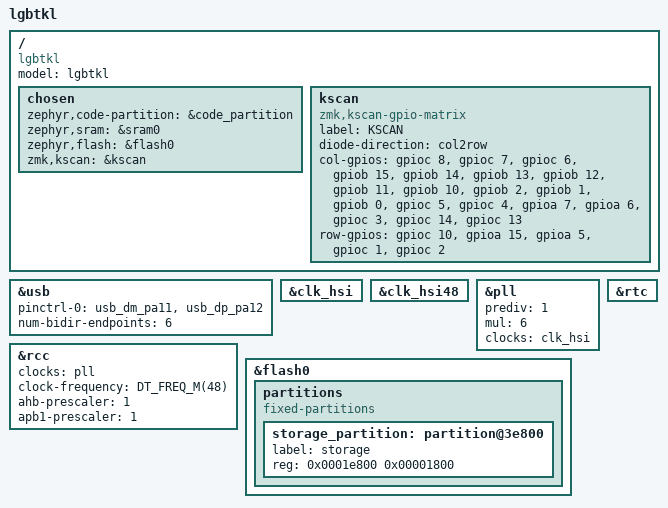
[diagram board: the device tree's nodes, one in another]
/*
 * Copyright (c) 2020 The ZMK Contributors
 *
 * SPDX-License-Identifier: MIT
 */

/dts-v1/;
#include <st/f0/stm32f072Xb.dtsi>
#include <st/f0/stm32f072v(8-b)tx-pinctrl.dtsi>

#include "lgbtkl-transforms.dtsi"
#include "lgbtkl-layouts.dtsi"

/ {
    model = "lgbtkl";
    compatible = "lgbtkl", "st,stm32f072";

    chosen {
        zephyr,code-partition = &code_partition;
        zephyr,sram = &sram0;
        zephyr,flash = &flash0;
        zmk,kscan = &kscan;
    };

    kscan: kscan {
        compatible = "zmk,kscan-gpio-matrix";
        label = "KSCAN";

        diode-direction = "col2row";

        col-gpios
        = <&gpioc 8 (GPIO_ACTIVE_HIGH | GPIO_PULL_DOWN)>
        , <&gpioc 7 (GPIO_ACTIVE_HIGH | GPIO_PULL_DOWN)>
        , <&gpioc 6 (GPIO_ACTIVE_HIGH | GPIO_PULL_DOWN)>
        , <&gpiob 15 (GPIO_ACTIVE_HIGH | GPIO_PULL_DOWN)>
        , <&gpiob 14 (GPIO_ACTIVE_HIGH | GPIO_PULL_DOWN)>
        , <&gpiob 13 (GPIO_ACTIVE_HIGH | GPIO_PULL_DOWN)>
        , <&gpiob 12 (GPIO_ACTIVE_HIGH | GPIO_PULL_DOWN)>
        , <&gpiob 11 (GPIO_ACTIVE_HIGH | GPIO_PULL_DOWN)>
        , <&gpiob 10 (GPIO_ACTIVE_HIGH | GPIO_PULL_DOWN)>
        , <&gpiob 2  (GPIO_ACTIVE_HIGH | GPIO_PULL_DOWN)>
        , <&gpiob 1 (GPIO_ACTIVE_HIGH | GPIO_PULL_DOWN)>
         , <&gpiob 0 (GPIO_ACTIVE_HIGH | GPIO_PULL_DOWN)>
         , <&gpioc 5 (GPIO_ACTIVE_HIGH | GPIO_PULL_DOWN)>
         , <&gpioc 4 (GPIO_ACTIVE_HIGH | GPIO_PULL_DOWN)>
         , <&gpioa 7 (GPIO_ACTIVE_HIGH | GPIO_PULL_DOWN)>
         , <&gpioa 6 (GPIO_ACTIVE_HIGH | GPIO_PULL_DOWN)>
         , <&gpioc 3 (GPIO_ACTIVE_HIGH | GPIO_PULL_DOWN)>
         , <&gpioc 14 (GPIO_ACTIVE_HIGH | GPIO_PULL_DOWN)>
         , <&gpioc 13 (GPIO_ACTIVE_HIGH | GPIO_PULL_DOWN)>
         ;
      row-gpios
        = <&gpioc 10  (GPIO_ACTIVE_HIGH | GPIO_PULL_DOWN)>
        , <&gpioa 15 (GPIO_ACTIVE_HIGH | GPIO_PULL_DOWN)>
        , <&gpioa 5 (GPIO_ACTIVE_HIGH | GPIO_PULL_DOWN)>
        , <&gpioc 1 (GPIO_ACTIVE_HIGH | GPIO_PULL_DOWN)>
        , <&gpioc 2 (GPIO_ACTIVE_HIGH | GPIO_PULL_DOWN)>
	;
    };

};

zephyr_udc0: &usb {
    status = "okay";

    pinctrl-0 = <&usb_dm_pa11 &usb_dp_pa12>;
    pinctrl-names = "default";

    num-bidir-endpoints = <6>;
};

&clk_hsi {
    status = "okay";
};

&clk_hsi48 {
    status = "okay";
};

&pll {
    prediv = <1>;
    mul = <6>;
    clocks = <&clk_hsi>;
    status = "okay";
};

&rcc {
    clocks = <&pll>;
    clock-frequency = <DT_FREQ_M(48)>;
    ahb-prescaler = <1>;
    apb1-prescaler = <1>;
};


&rtc {
    status = "okay";
};

&flash0 {
    /*
     * For more information, see:
     * http: //docs.zephyrproject.org/latest/guides/dts/index.html#flash-partitions
     */
    partitions {
        compatible = "fixed-partitions";
        #address-cells = <1>;
        #size-cells = <1>;

        /* Set 6Kb of storage at the end of the 128Kb of flash */
        storage_partition: partition@3e800 {
            label = "storage";
            reg = <0x0001e800 0x00001800>;
        };
    };
};
